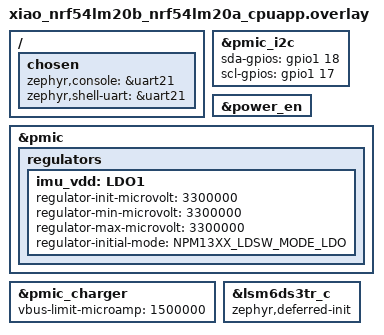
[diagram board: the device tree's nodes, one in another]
#include <zephyr/dt-bindings/regulator/npm13xx.h>

/ {
	chosen {
		zephyr,console = &uart21;
		zephyr,shell-uart = &uart21;
	};
};

&pmic_i2c {
	sda-gpios = <&gpio1 18 GPIO_ACTIVE_HIGH>;
	scl-gpios = <&gpio1 17 GPIO_ACTIVE_HIGH>;
	status = "okay";
};

&power_en {
	/delete-property/ regulator-boot-on;
};

&pmic {
	regulators {
		imu_vdd: LDO1 {
			/delete-property/ regulator-boot-on;
			regulator-init-microvolt = <3300000>;
			regulator-min-microvolt = <3300000>;
			regulator-max-microvolt = <3300000>;
			regulator-initial-mode = <NPM13XX_LDSW_MODE_LDO>;
		};
	};
};

&pmic_charger {
	vbus-limit-microamp = <1500000>;
};

&lsm6ds3tr_c {
	zephyr,deferred-init;
};
